AUTOSAR XML (schema 314)
package /ComponentType
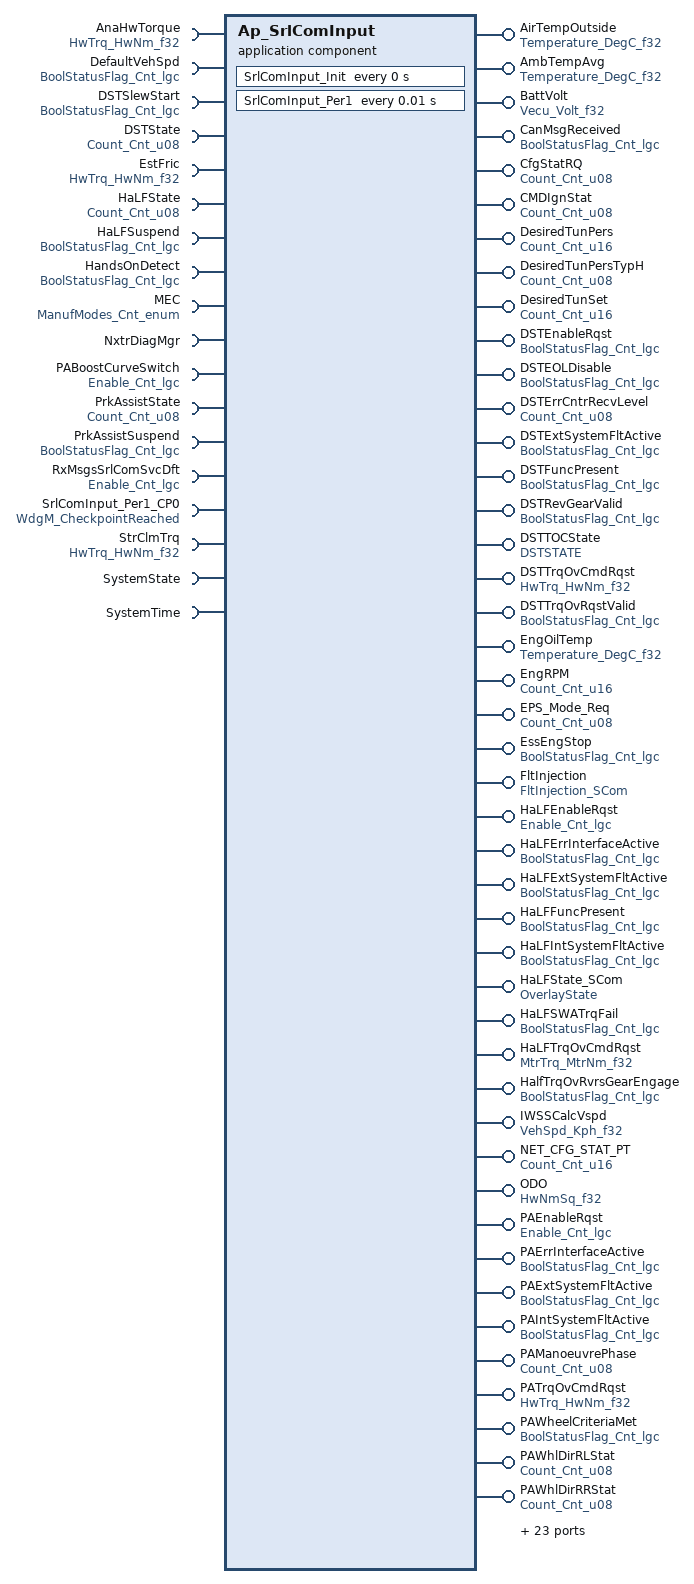
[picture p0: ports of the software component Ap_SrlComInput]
  application software component type Ap_SrlComInput
    67 x provide port:
      AirTempOutside: unqueued-sender-com-spec{data-element=DegC_f32, can-invalidate=false, init-value=D_ZERO_ULS_F32}, provided-interface=Temperature_DegC_f32
      AmbTempAvg: unqueued-sender-com-spec{data-element=DegC_f32, can-invalidate=false, init-value=D_ZERO_ULS_F32}, provided-interface=Temperature_DegC_f32
      BattVolt: unqueued-sender-com-spec{data-element=Volt_f32, can-invalidate=false, init-value=D_ZERO_ULS_F32}, provided-interface=Vecu_Volt_f32
      CanMsgReceived: unqueued-sender-com-spec{data-element=Cnt_lgc, can-invalidate=false, init-value=D_FALSE_CNT_LGC}, provided-interface=BoolStatusFlag_Cnt_lgc
      CfgStatRQ: unqueued-sender-com-spec{data-element=Cnt_u08, can-invalidate=false, init-value=D_ZERO_CNT_U8}, provided-interface=Count_Cnt_u08
      CMDIgnStat: unqueued-sender-com-spec{data-element=Cnt_u08, can-invalidate=false, init-value=D_ZERO_CNT_U8}, provided-interface=Count_Cnt_u08
      DesiredTunPers: unqueued-sender-com-spec{data-element=Cnt_u16, can-invalidate=false, init-value=D_ZERO_CNT_U16}, provided-interface=Count_Cnt_u16
      DesiredTunPersTypH: unqueued-sender-com-spec{data-element=Cnt_u08, can-invalidate=false, init-value=D_ZERO_CNT_U8}, provided-interface=Count_Cnt_u08
      DesiredTunSet: unqueued-sender-com-spec{data-element=Cnt_u16, can-invalidate=false, init-value=D_ZERO_CNT_U16}, provided-interface=Count_Cnt_u16
      DSTEnableRqst: unqueued-sender-com-spec{data-element=Cnt_lgc, can-invalidate=false, init-value=D_FALSE_CNT_LGC}, provided-interface=BoolStatusFlag_Cnt_lgc
      DSTEOLDisable: unqueued-sender-com-spec{data-element=Cnt_lgc, can-invalidate=false, init-value=D_FALSE_CNT_LGC}, provided-interface=BoolStatusFlag_Cnt_lgc
      DSTErrCntrRecvLevel: unqueued-sender-com-spec{data-element=Cnt_u08, can-invalidate=false, init-value=D_ZERO_CNT_U8}, provided-interface=Count_Cnt_u08
      DSTExtSystemFltActive: unqueued-sender-com-spec{data-element=Cnt_lgc, can-invalidate=false, init-value=D_FALSE_CNT_LGC}, provided-interface=BoolStatusFlag_Cnt_lgc
      DSTFuncPresent: unqueued-sender-com-spec{data-element=Cnt_lgc, can-invalidate=false, init-value=D_FALSE_CNT_LGC}, provided-interface=BoolStatusFlag_Cnt_lgc
      DSTRevGearValid: unqueued-sender-com-spec{data-element=Cnt_lgc, can-invalidate=false, init-value=D_FALSE_CNT_LGC}, provided-interface=BoolStatusFlag_Cnt_lgc
      DSTTOCState: unqueued-sender-com-spec{data-element=Uls_enum, can-invalidate=false, init-value=D_DSTINITVAL_U8}, provided-interface=DSTSTATE
      DSTTrqOvCmdRqst: unqueued-sender-com-spec{data-element=HwNm_f32, can-invalidate=false, init-value=D_ZERO_ULS_F32}, provided-interface=HwTrq_HwNm_f32
      DSTTrqOvRqstValid: unqueued-sender-com-spec{data-element=Cnt_lgc, can-invalidate=false, init-value=D_FALSE_CNT_LGC}, provided-interface=BoolStatusFlag_Cnt_lgc
      EngOilTemp: unqueued-sender-com-spec{data-element=DegC_f32, can-invalidate=false, init-value=D_ZERO_ULS_F32}, provided-interface=Temperature_DegC_f32
      EngRPM: unqueued-sender-com-spec{data-element=Cnt_u16, can-invalidate=false, init-value=D_ONE_CNT_U16}, provided-interface=Count_Cnt_u16
      EPS_Mode_Req: unqueued-sender-com-spec{data-element=Cnt_u08, can-invalidate=false, init-value=D_ZERO_CNT_U8}, provided-interface=Count_Cnt_u08
      EssEngStop: unqueued-sender-com-spec{data-element=Cnt_lgc, can-invalidate=false, init-value=D_TRUE_CNT_LGC}, provided-interface=BoolStatusFlag_Cnt_lgc
      FltInjection: server-com-spec{operation=FltInjection, queue-length=1}, provided-interface=FltInjection_SCom
      HaLFEnableRqst: unqueued-sender-com-spec{data-element=Cnt_lgc, can-invalidate=false, init-value=D_FALSE_CNT_LGC}, provided-interface=Enable_Cnt_lgc
      HaLFErrInterfaceActive: unqueued-sender-com-spec{data-element=Cnt_lgc, can-invalidate=false, init-value=D_FALSE_CNT_LGC}, provided-interface=BoolStatusFlag_Cnt_lgc
      HaLFExtSystemFltActive: unqueued-sender-com-spec{data-element=Cnt_lgc, can-invalidate=false, init-value=D_FALSE_CNT_LGC}, provided-interface=BoolStatusFlag_Cnt_lgc
      HaLFFuncPresent: unqueued-sender-com-spec{data-element=Cnt_lgc, can-invalidate=false, init-value=D_FALSE_CNT_LGC}, provided-interface=BoolStatusFlag_Cnt_lgc
      HaLFIntSystemFltActive: unqueued-sender-com-spec{data-element=Cnt_lgc, can-invalidate=false, init-value=D_FALSE_CNT_LGC}, provided-interface=BoolStatusFlag_Cnt_lgc
      HaLFState_SCom: server-com-spec{operation=Transition, queue-length=1}, provided-interface=OverlayState
      HaLFSWATrqFail: unqueued-sender-com-spec{data-element=Cnt_lgc, can-invalidate=false, init-value=D_FALSE_CNT_LGC}, provided-interface=BoolStatusFlag_Cnt_lgc
      HaLFTrqOvCmdRqst: unqueued-sender-com-spec{data-element=MtrNm_f32, can-invalidate=false, init-value=D_ZERO_ULS_F32}, provided-interface=MtrTrq_MtrNm_f32
      HalfTrqOvRvrsGearEngage: unqueued-sender-com-spec{data-element=Cnt_lgc, can-invalidate=false, init-value=D_FALSE_CNT_LGC}, provided-interface=BoolStatusFlag_Cnt_lgc
      IWSSCalcVspd: unqueued-sender-com-spec{data-element=Kph_f32, can-invalidate=false, init-value=D_ZERO_ULS_F32}, provided-interface=VehSpd_Kph_f32
      NET_CFG_STAT_PT: unqueued-sender-com-spec{data-element=Cnt_u16, can-invalidate=false, init-value=D_ZERO_CNT_U16}, provided-interface=Count_Cnt_u16
      ODO: unqueued-sender-com-spec{data-element=HwNmSq_f32, can-invalidate=false, init-value=D_ZERO_ULS_F32}, provided-interface=HwNmSq_f32
      PAEnableRqst: unqueued-sender-com-spec{data-element=Cnt_lgc, can-invalidate=false, init-value=D_FALSE_CNT_LGC}, provided-interface=Enable_Cnt_lgc
      PAErrInterfaceActive: unqueued-sender-com-spec{data-element=Cnt_lgc, can-invalidate=false, init-value=D_FALSE_CNT_LGC}, provided-interface=BoolStatusFlag_Cnt_lgc
      PAExtSystemFltActive: unqueued-sender-com-spec{data-element=Cnt_lgc, can-invalidate=false, init-value=D_FALSE_CNT_LGC}, provided-interface=BoolStatusFlag_Cnt_lgc
      PAIntSystemFltActive: unqueued-sender-com-spec{data-element=Cnt_lgc, can-invalidate=false, init-value=D_FALSE_CNT_LGC}, provided-interface=BoolStatusFlag_Cnt_lgc
      PAManoeuvrePhase: unqueued-sender-com-spec{data-element=Cnt_u08, can-invalidate=false, init-value=D_ZERO_CNT_U8}, provided-interface=Count_Cnt_u08
      PATrqOvCmdRqst: unqueued-sender-com-spec{data-element=HwNm_f32, can-invalidate=false, init-value=D_ZERO_ULS_F32}, provided-interface=HwTrq_HwNm_f32
      PAWheelCriteriaMet: unqueued-sender-com-spec{data-element=Cnt_lgc, can-invalidate=false, init-value=D_FALSE_CNT_LGC}, provided-interface=BoolStatusFlag_Cnt_lgc
      PAWhlDirRLStat: unqueued-sender-com-spec{data-element=Cnt_u08, can-invalidate=false, init-value=D_PAWHLDIRINVALID_CNT_U08}, provided-interface=Count_Cnt_u08
      PAWhlDirRRStat: unqueued-sender-com-spec{data-element=Cnt_u08, can-invalidate=false, init-value=D_PAWHLDIRINVALID_CNT_U08}, provided-interface=Count_Cnt_u08
      PAWhlPlsCntRLValid: unqueued-sender-com-spec{data-element=Cnt_lgc, can-invalidate=false, init-value=D_FALSE_CNT_LGC}, provided-interface=Validity_Cnt_lgc
      PAWhlPlsCntRRValid: unqueued-sender-com-spec{data-element=Cnt_lgc, can-invalidate=false, init-value=D_FALSE_CNT_LGC}, provided-interface=Validity_Cnt_lgc
      PrevHaLFEnableRqst: unqueued-sender-com-spec{data-element=Cnt_lgc, can-invalidate=false, init-value=D_FALSE_CNT_LGC}, provided-interface=Enable_Cnt_lgc
      PrevHaLFTrqOvCmdRqst: unqueued-sender-com-spec{data-element=MtrNm_f32, can-invalidate=false, init-value=D_ZERO_ULS_F32}, provided-interface=MtrTrq_MtrNm_f32
      PrkAssistState_SCom: server-com-spec{operation=Transition, queue-length=1}, provided-interface=OverlayState
      PrkAsstFuncPresent: unqueued-sender-com-spec{data-element=Cnt_lgc, can-invalidate=false, init-value=D_FALSE_CNT_LGC}, provided-interface=BoolStatusFlag_Cnt_lgc
      SCom_ManualVehSpd: server-com-spec{operation=SCom_ManualVehSpd, queue-length=1}, provided-interface=SCom_ManualVehSpd
      SpStPrsnt: unqueued-sender-com-spec{data-element=Cnt_lgc, can-invalidate=false, init-value=D_FALSE_CNT_LGC}, provided-interface=BoolStatusFlag_Cnt_lgc
      SrlComLWhlSpd: unqueued-sender-com-spec{data-element=Hz_f32, can-invalidate=false, init-value=D_ZERO_ULS_F32}, provided-interface=WhlSpd_Hz_f32
      SrlComLWhlSpdVld: unqueued-sender-com-spec{data-element=Cnt_lgc, can-invalidate=false, init-value=D_FALSE_CNT_LGC}, provided-interface=Validity_Cnt_lgc
      SrlComRWhlSpd: unqueued-sender-com-spec{data-element=Hz_f32, can-invalidate=false, init-value=D_ZERO_ULS_F32}, provided-interface=WhlSpd_Hz_f32
      SrlComRWhlSpdVld: unqueued-sender-com-spec{data-element=Cnt_lgc, can-invalidate=false, init-value=D_FALSE_CNT_LGC}, provided-interface=Validity_Cnt_lgc
      SrlComVehSpd: unqueued-sender-com-spec{data-element=Kph_f32, can-invalidate=false, init-value=D_ZERO_ULS_F32}, provided-interface=VehSpd_Kph_f32
      SrlComVehSpdValid: unqueued-sender-com-spec{data-element=Cnt_lgc, can-invalidate=false, init-value=D_FALSE_CNT_LGC}, provided-interface=BoolStatusFlag_Cnt_lgc
      StrgWhlAngl: unqueued-sender-com-spec{data-element=HwDeg_f32, can-invalidate=false, init-value=D_ZERO_ULS_F32}, provided-interface=HwPos_HwDeg_f32
      StrgWhlAnglValid: unqueued-sender-com-spec{data-element=Cnt_lgc, can-invalidate=false, init-value=D_FALSE_CNT_LGC}, provided-interface=Validity_Cnt_lgc
      TrqOvReverseGearEngage: unqueued-sender-com-spec{data-element=Cnt_lgc, can-invalidate=false, init-value=D_FALSE_CNT_LGC}, provided-interface=BoolStatusFlag_Cnt_lgc
      VCBodyStyle: unqueued-sender-com-spec{data-element=Cnt_u08, can-invalidate=false, init-value=D_ZERO_CNT_U8}, provided-interface=Count_Cnt_u08
      VCCountry: unqueued-sender-com-spec{data-element=Cnt_u08, can-invalidate=false, init-value=D_ZERO_CNT_U8}, provided-interface=Count_Cnt_u08
      VCModelYear: unqueued-sender-com-spec{data-element=Cnt_u08, can-invalidate=false, init-value=D_ZERO_CNT_U8}, provided-interface=Count_Cnt_u08
      VCVehLine: unqueued-sender-com-spec{data-element=Cnt_u08, can-invalidate=false, init-value=D_ZERO_CNT_U8}, provided-interface=Count_Cnt_u08
      VehAccel: unqueued-sender-com-spec{data-element=KphpS_f32, can-invalidate=false, init-value=D_ZERO_ULS_F32}, provided-interface=KphpS_f32
      VehAccelX: unqueued-sender-com-spec{data-element=KphpS_f32, can-invalidate=false, init-value=D_ZERO_ULS_F32}, provided-interface=KphpS_f32
    18 x require port:
      AnaHwTorque: unqueued-receiver-com-spec{data-element=HwNm_f32, init-value=D_ZERO_ULS_F32}, required-interface=HwTrq_HwNm_f32
      DefaultVehSpd: unqueued-receiver-com-spec{data-element=Cnt_lgc, init-value=D_FALSE_CNT_LGC}, required-interface=BoolStatusFlag_Cnt_lgc
      DSTSlewStart: unqueued-receiver-com-spec{data-element=Cnt_lgc, init-value=D_FALSE_CNT_LGC}, required-interface=BoolStatusFlag_Cnt_lgc
      DSTState: unqueued-receiver-com-spec{data-element=Cnt_u08, init-value=D_ZERO_CNT_U8}, required-interface=Count_Cnt_u08
      EstFric: unqueued-receiver-com-spec{data-element=HwNm_f32, init-value=D_ZERO_ULS_F32}, required-interface=HwTrq_HwNm_f32
      HaLFState: unqueued-receiver-com-spec{data-element=Cnt_u08, init-value=D_ZERO_CNT_U8}, required-interface=Count_Cnt_u08
      HaLFSuspend: unqueued-receiver-com-spec{data-element=Cnt_lgc, init-value=D_FALSE_CNT_LGC}, required-interface=BoolStatusFlag_Cnt_lgc
      HandsOnDetect: unqueued-receiver-com-spec{data-element=Cnt_lgc, init-value=D_FALSE_CNT_LGC}, required-interface=BoolStatusFlag_Cnt_lgc
      MEC: unqueued-receiver-com-spec{data-element=Cnt_enum, init-value=D_MANUFMODEINIT_CNT_ENUM}, required-interface=ManufModes_Cnt_enum
      NxtrDiagMgr: required-com-specs=[GetNTCActive, GetNTCFailed, GetNTCStatus, SetNTCStatus], required-interface=NxtrDiagMgr
      PABoostCurveSwitch: unqueued-receiver-com-spec{data-element=Cnt_lgc, init-value=D_FALSE_CNT_LGC}, required-interface=Enable_Cnt_lgc
      PrkAssistState: unqueued-receiver-com-spec{data-element=Cnt_u08, init-value=D_ZERO_CNT_U8}, required-interface=Count_Cnt_u08
      PrkAssistSuspend: unqueued-receiver-com-spec{data-element=Cnt_lgc, init-value=D_FALSE_CNT_LGC}, required-interface=BoolStatusFlag_Cnt_lgc
      RxMsgsSrlComSvcDft: unqueued-receiver-com-spec{data-element=Cnt_lgc, init-value=D_FALSE_CNT_LGC}, required-interface=Enable_Cnt_lgc
      SrlComInput_Per1_CP0: client-com-spec=CheckpointReached, required-interface=WdgM_CheckpointReached
      StrClmTrq: unqueued-receiver-com-spec{data-element=HwNm_f32, init-value=D_ZERO_ULS_F32}, required-interface=HwTrq_HwNm_f32
      SystemState: required-interface=SystemState
      SystemTime: required-interface=SystemTime
        required-com-specs:
          DtrmnElapsedTime_mS_u16
          DtrmnElapsedTime_mS_u32
          DtrmnElapsedTime_uS_u16
          DtrmnElapsedTime_uS_u32
          GetSystemTime_mS_u32
          GetSystemTime_uS_u32
  internal behavior Ap_SrlComInput_InternalBehavior: component=Ap_SrlComInput
    operation invoked event OIT_FaultInjection_FltInjection_FltInjection_FltInjection: start-on-event=FaultInjection_FltInjection, operation=FltInjection.FltInjection
    operation invoked event OIT_HaLFState_SCom_Transition_HaLFState_SCom_Transition: start-on-event=HaLFState_SCom_Transition, operation=HaLFState_SCom.Transition
    operation invoked event OIT_PrkAssistState_SCom_Transition_PrkAssistState_SCom_Transition: start-on-event=PrkAssistState_SCom_Transition, operation=PrkAssistState_SCom.Transition
    timing event SrlComInput_InitEvent: start-on-event=SrlComInput_Init, period=0
    timing event TMT_SrlComInput_Per1: start-on-event=SrlComInput_Per1, period=0.01
    operation invoked event OIT_SrlComInput_SCom_ManualVehSpd_SCom_ManualVehSpd_SCom_ManualVehSpd: start-on-event=SrlComInput_SCom_ManualVehSpd, operation=SCom_ManualVehSpd.SCom_ManualVehSpd
    port-api-options:
      enable-take-address=false, indirect-api=false, port=AirTempOutside
      enable-take-address=false, indirect-api=false, port=AmbTempAvg
      enable-take-address=false, indirect-api=false, port=AnaHwTorque
      enable-take-address=false, indirect-api=false, port=BattVolt
      enable-take-address=false, indirect-api=false, port=CanMsgReceived
      enable-take-address=false, indirect-api=false, port=CfgStatRQ
      enable-take-address=false, indirect-api=false, port=CMDIgnStat
      enable-take-address=false, indirect-api=false, port=DefaultVehSpd
      enable-take-address=false, indirect-api=false, port=DesiredTunPers
      enable-take-address=false, indirect-api=false, port=DesiredTunPersTypH
      enable-take-address=false, indirect-api=false, port=DesiredTunSet
      enable-take-address=false, indirect-api=false, port=DSTEnableRqst
      enable-take-address=false, indirect-api=false, port=DSTEOLDisable
      enable-take-address=false, indirect-api=false, port=DSTErrCntrRecvLevel
      enable-take-address=false, indirect-api=false, port=DSTExtSystemFltActive
      enable-take-address=false, indirect-api=false, port=DSTFuncPresent
      enable-take-address=false, indirect-api=false, port=DSTRevGearValid
      enable-take-address=false, indirect-api=false, port=DSTSlewStart
      enable-take-address=false, indirect-api=false, port=DSTState
      enable-take-address=false, indirect-api=false, port=DSTTOCState
      enable-take-address=false, indirect-api=false, port=DSTTrqOvCmdRqst
      enable-take-address=false, indirect-api=false, port=DSTTrqOvRqstValid
      enable-take-address=false, indirect-api=false, port=EngOilTemp
      enable-take-address=false, indirect-api=false, port=EngRPM
      enable-take-address=false, indirect-api=false, port=EPS_Mode_Req
      enable-take-address=false, indirect-api=false, port=EssEngStop
      enable-take-address=false, indirect-api=false, port=EstFric
      enable-take-address=false, indirect-api=false, port=FltInjection
      enable-take-address=false, indirect-api=false, port=HaLFEnableRqst
      enable-take-address=false, indirect-api=false, port=HaLFErrInterfaceActive
      enable-take-address=false, indirect-api=false, port=HaLFExtSystemFltActive
      enable-take-address=false, indirect-api=false, port=HaLFFuncPresent
      enable-take-address=false, indirect-api=false, port=HaLFIntSystemFltActive
      enable-take-address=false, indirect-api=false, port=HaLFState
      enable-take-address=false, indirect-api=false, port=HaLFState_SCom
      enable-take-address=false, indirect-api=false, port=HaLFSuspend
      enable-take-address=false, indirect-api=false, port=HaLFSWATrqFail
      enable-take-address=false, indirect-api=false, port=HaLFTrqOvCmdRqst
      enable-take-address=false, indirect-api=false, port=HalfTrqOvRvrsGearEngage
      enable-take-address=false, indirect-api=false, port=HandsOnDetect
      enable-take-address=false, indirect-api=false, port=IWSSCalcVspd
      enable-take-address=false, indirect-api=false, port=MEC
      enable-take-address=false, indirect-api=false, port=NET_CFG_STAT_PT
      enable-take-address=false, indirect-api=false, port=NxtrDiagMgr
      enable-take-address=false, indirect-api=false, port=ODO
      enable-take-address=false, indirect-api=false, port=PABoostCurveSwitch
      enable-take-address=false, indirect-api=false, port=PAEnableRqst
      enable-take-address=false, indirect-api=false, port=PAErrInterfaceActive
      enable-take-address=false, indirect-api=false, port=PAExtSystemFltActive
      enable-take-address=false, indirect-api=false, port=PAIntSystemFltActive
      enable-take-address=false, indirect-api=false, port=PAManoeuvrePhase
      enable-take-address=false, indirect-api=false, port=PATrqOvCmdRqst
      enable-take-address=false, indirect-api=false, port=PAWheelCriteriaMet
      enable-take-address=false, indirect-api=false, port=PAWhlDirRLStat
      enable-take-address=false, indirect-api=false, port=PAWhlDirRRStat
      enable-take-address=false, indirect-api=false, port=PAWhlPlsCntRLValid
      enable-take-address=false, indirect-api=false, port=PAWhlPlsCntRRValid
      enable-take-address=false, indirect-api=false, port=PrevHaLFEnableRqst
      enable-take-address=false, indirect-api=false, port=PrevHaLFTrqOvCmdRqst
      enable-take-address=false, indirect-api=false, port=PrkAssistState
      enable-take-address=false, indirect-api=false, port=PrkAssistState_SCom
      enable-take-address=false, indirect-api=false, port=PrkAssistSuspend
      enable-take-address=false, indirect-api=false, port=PrkAsstFuncPresent
      enable-take-address=false, indirect-api=false, port=RxMsgsSrlComSvcDft
      enable-take-address=false, indirect-api=false, port=SCom_ManualVehSpd
      enable-take-address=false, indirect-api=false, port=SpStPrsnt
      enable-take-address=false, indirect-api=false, port=SrlComInput_Per1_CP0
      enable-take-address=false, indirect-api=false, port=SrlComLWhlSpd
      enable-take-address=false, indirect-api=false, port=SrlComLWhlSpdVld
      enable-take-address=false, indirect-api=false, port=SrlComRWhlSpd
      enable-take-address=false, indirect-api=false, port=SrlComRWhlSpdVld
      enable-take-address=false, indirect-api=false, port=SrlComVehSpd
      enable-take-address=false, indirect-api=false, port=SrlComVehSpdValid
      enable-take-address=false, indirect-api=false, port=StrClmTrq
      enable-take-address=false, indirect-api=false, port=StrgWhlAngl
      enable-take-address=false, indirect-api=false, port=StrgWhlAnglValid
      enable-take-address=false, indirect-api=false, port=SystemState
      enable-take-address=false, indirect-api=false, port=SystemTime
      enable-take-address=false, indirect-api=false, port=TrqOvReverseGearEngage
      enable-take-address=false, indirect-api=false, port=VCBodyStyle
      enable-take-address=false, indirect-api=false, port=VCCountry
      enable-take-address=false, indirect-api=false, port=VCModelYear
      enable-take-address=false, indirect-api=false, port=VCVehLine
      enable-take-address=false, indirect-api=false, port=VehAccel
      enable-take-address=false, indirect-api=false, port=VehAccelX
    6 x runnable:
      FaultInjection_FltInjection: can-be-invoked-concurrently=true
      HaLFState_SCom_Transition: can-be-invoked-concurrently=true
      PrkAssistState_SCom_Transition: can-be-invoked-concurrently=true
      SrlComInput_Init
      SrlComInput_Per1
        14 x data receive point:
          REC_AnaHwTorque_HwNm_f32: data-element=AnaHwTorque.HwNm_f32
          REC_DefaultVehSpd_Cnt_lgc: data-element=DefaultVehSpd.Cnt_lgc
          REC_DSTSlewStart_Cnt_lgc: data-element=DSTSlewStart.Cnt_lgc
          REC_DSTState_Cnt_u08: data-element=DSTState.Cnt_u08
          REC_EstFric_HwNm_f32: data-element=EstFric.HwNm_f32
          REC_HaLFState_Cnt_u08: data-element=HaLFState.Cnt_u08
          REC_HaLFSuspend_Cnt_lgc: data-element=HaLFSuspend.Cnt_lgc
          REC_HandsOnDetect_Cnt_lgc: data-element=HandsOnDetect.Cnt_lgc
          REC_MEC_Cnt_enum: data-element=MEC.Cnt_enum
          REC_PABoostCurveSwitch_Cnt_lgc: data-element=PABoostCurveSwitch.Cnt_lgc
          REC_PrkAssistState_Cnt_u08: data-element=PrkAssistState.Cnt_u08
          REC_PrkAssistSuspend_Cnt_lgc: data-element=PrkAssistSuspend.Cnt_lgc
          REC_RxMsgsSrlComSvcDft_Cnt_lgc: data-element=RxMsgsSrlComSvcDft.Cnt_lgc
          REC_StrClmTrq_HwNm_f32: data-element=StrClmTrq.HwNm_f32
        63 x data send point:
          SEND_AirTempOutside_DegC_f32: data-element=AirTempOutside.DegC_f32
          SEND_AmbTempAvg_DegC_f32: data-element=AmbTempAvg.DegC_f32
          SEND_BattVolt_Volt_f32: data-element=BattVolt.Volt_f32
          SEND_CanMsgReceived_Cnt_lgc: data-element=CanMsgReceived.Cnt_lgc
          SEND_CfgStatRQ_Cnt_u08: data-element=CfgStatRQ.Cnt_u08
          SEND_CMDIgnStat_Cnt_u08: data-element=CMDIgnStat.Cnt_u08
          SEND_DesiredTunPers_Cnt_u16: data-element=DesiredTunPers.Cnt_u16
          SEND_DesiredTunPersTypH_Cnt_u08: data-element=DesiredTunPersTypH.Cnt_u08
          SEND_DesiredTunSet_Cnt_u16: data-element=DesiredTunSet.Cnt_u16
          SEND_DSTEnableRqst_Cnt_lgc: data-element=DSTEnableRqst.Cnt_lgc
          SEND_DSTEOLDisable_Cnt_lgc: data-element=DSTEOLDisable.Cnt_lgc
          SEND_DSTErrCntrRecvLevel_Cnt_u08: data-element=DSTErrCntrRecvLevel.Cnt_u08
          SEND_DSTExtSystemFltActive_Cnt_lgc: data-element=DSTExtSystemFltActive.Cnt_lgc
          SEND_DSTFuncPresent_Cnt_lgc: data-element=DSTFuncPresent.Cnt_lgc
          SEND_DSTRevGearValid_Cnt_lgc: data-element=DSTRevGearValid.Cnt_lgc
          SEND_DSTTOCState_Uls_enum: data-element=DSTTOCState.Uls_enum
          SEND_DSTTrqOvCmdRqst_HwNm_f32: data-element=DSTTrqOvCmdRqst.HwNm_f32
          SEND_DSTTrqOvRqstValid_Cnt_lgc: data-element=DSTTrqOvRqstValid.Cnt_lgc
          SEND_EngOilTemp_DegC_f32: data-element=EngOilTemp.DegC_f32
          SEND_EngRPM_Cnt_u16: data-element=EngRPM.Cnt_u16
          SEND_EPS_Mode_Req_Cnt_u08: data-element=EPS_Mode_Req.Cnt_u08
          SEND_EssEngStop_Cnt_lgc: data-element=EssEngStop.Cnt_lgc
          SEND_HaLFEnableRqst_Cnt_lgc: data-element=HaLFEnableRqst.Cnt_lgc
          SEND_HaLFErrInterfaceActive_Cnt_lgc: data-element=HaLFErrInterfaceActive.Cnt_lgc
          SEND_HaLFExtSystemFltActive_Cnt_lgc: data-element=HaLFExtSystemFltActive.Cnt_lgc
          SEND_HaLFFuncPresent_Cnt_lgc: data-element=HaLFFuncPresent.Cnt_lgc
          SEND_HaLFIntSystemFltActive_Cnt_lgc: data-element=HaLFIntSystemFltActive.Cnt_lgc
          SEND_HaLFSWATrqFail_Cnt_lgc: data-element=HaLFSWATrqFail.Cnt_lgc
          SEND_HaLFTrqOvCmdRqst_MtrNm_f32: data-element=HaLFTrqOvCmdRqst.MtrNm_f32
          SEND_HalfTrqOvRvrsGearEngage_Cnt_lgc: data-element=HalfTrqOvRvrsGearEngage.Cnt_lgc
          SEND_IWSSCalcVspd_Kph_f32: data-element=IWSSCalcVspd.Kph_f32
          SEND_NET_CFG_STAT_PT_Cnt_u16: data-element=NET_CFG_STAT_PT.Cnt_u16
          SEND_ODO_HwNmSq_f32: data-element=ODO.HwNmSq_f32
          SEND_PAEnableRqst_Cnt_lgc: data-element=PAEnableRqst.Cnt_lgc
          SEND_PAErrInterfaceActive_Cnt_lgc: data-element=PAErrInterfaceActive.Cnt_lgc
          SEND_PAExtSystemFltActive_Cnt_lgc: data-element=PAExtSystemFltActive.Cnt_lgc
          SEND_PAIntSystemFltActive_Cnt_lgc: data-element=PAIntSystemFltActive.Cnt_lgc
          SEND_PAManoeuvrePhase_Cnt_u08: data-element=PAManoeuvrePhase.Cnt_u08
          SEND_PATrqOvCmdRqst_HwNm_f32: data-element=PATrqOvCmdRqst.HwNm_f32
          SEND_PAWheelCriteriaMet_Cnt_lgc: data-element=PAWheelCriteriaMet.Cnt_lgc
          SEND_PAWhlDirRLStat_Cnt_u08: data-element=PAWhlDirRLStat.Cnt_u08
          SEND_PAWhlDirRRStat_Cnt_u08: data-element=PAWhlDirRRStat.Cnt_u08
          SEND_PAWhlPlsCntRLValid_Cnt_lgc: data-element=PAWhlPlsCntRLValid.Cnt_lgc
          SEND_PAWhlPlsCntRRValid_Cnt_lgc: data-element=PAWhlPlsCntRRValid.Cnt_lgc
          SEND_PrevHaLFEnableRqst_Cnt_lgc: data-element=PrevHaLFEnableRqst.Cnt_lgc
          SEND_PrevHaLFTrqOvCmdRqst_MtrNm_f32: data-element=PrevHaLFTrqOvCmdRqst.MtrNm_f32
          SEND_PrkAsstFuncPresent_Cnt_lgc: data-element=PrkAsstFuncPresent.Cnt_lgc
          SEND_SpStPrsnt_Cnt_lgc: data-element=SpStPrsnt.Cnt_lgc
          SEND_SrlComLWhlSpd_Hz_f32: data-element=SrlComLWhlSpd.Hz_f32
          SEND_SrlComLWhlSpdVld_Cnt_lgc: data-element=SrlComLWhlSpdVld.Cnt_lgc
          SEND_SrlComRWhlSpd_Hz_f32: data-element=SrlComRWhlSpd.Hz_f32
          SEND_SrlComRWhlSpdVld_Cnt_lgc: data-element=SrlComRWhlSpdVld.Cnt_lgc
          SEND_SrlComVehSpd_Kph_f32: data-element=SrlComVehSpd.Kph_f32
          SEND_SrlComVehSpdValid_Cnt_lgc: data-element=SrlComVehSpdValid.Cnt_lgc
          SEND_StrgWhlAngl_HwDeg_f32: data-element=StrgWhlAngl.HwDeg_f32
          SEND_StrgWhlAnglValid_Cnt_lgc: data-element=StrgWhlAnglValid.Cnt_lgc
          SEND_TrqOvReverseGearEngage_Cnt_lgc: data-element=TrqOvReverseGearEngage.Cnt_lgc
          SEND_VCBodyStyle_Cnt_u08: data-element=VCBodyStyle.Cnt_u08
          SEND_VCCountry_Cnt_u08: data-element=VCCountry.Cnt_u08
          SEND_VCModelYear_Cnt_u08: data-element=VCModelYear.Cnt_u08
          SEND_VCVehLine_Cnt_u08: data-element=VCVehLine.Cnt_u08
          SEND_VehAccel_KphpS_f32: data-element=VehAccel.KphpS_f32
          SEND_VehAccelX_KphpS_f32: data-element=VehAccelX.KphpS_f32
        7 x sync call, all with timeout=0:
          SC_NxtrDiagMgr_GetNTCFailed: operation=NxtrDiagMgr.GetNTCFailed
          SC_NxtrDiagMgr_GetNTCStatus: operation=NxtrDiagMgr.GetNTCStatus
          SC_NxtrDiagMgr_SetNTCStatus: operation=NxtrDiagMgr.SetNTCStatus
          SC_SrlComInput_Per1_CP0_CheckpointReached: operation=SrlComInput_Per1_CP0.CheckpointReached
          SC_SystemTime_DtrmnElapsedTime_mS_u16: operation=SystemTime.DtrmnElapsedTime_mS_u16
          SC_SystemTime_DtrmnElapsedTime_mS_u32: operation=SystemTime.DtrmnElapsedTime_mS_u32
          SC_SystemTime_GetSystemTime_mS_u32: operation=SystemTime.GetSystemTime_mS_u32
      SrlComInput_SCom_ManualVehSpd: can-be-invoked-concurrently=true
  swc implementation Ap_SrlComInput_Implementation: behavior=Ap_SrlComInput_InternalBehavior
    code-descriptors:
      code Code: type=SRC
